# AT91SAM9CN11 register map
Vendor: Atmel; Series: SAM9CN; File version: 20130208
Registers are 32-bit, read-only, reset 0x0 unless marked. A register's access mark holds for its fields unless they carry their own. Offsets are from the block's base; [hi:lo] are bit positions; {n}, {i} and the like mark numbered series.

## AES — Advanced Encryption Standard
Base 0xF000C000; register names take the prefix AES_
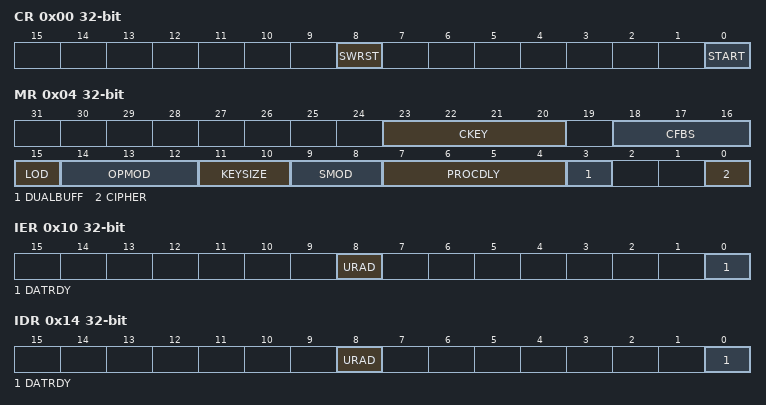
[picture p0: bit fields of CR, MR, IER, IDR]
0x00 CR wo reset not defined — Control Register
  [8] SWRST — Software Reset
  [0] START — Start Processing
0x04 MR rw — Mode Register
  [23:20] CKEY — Key
  [18:16] CFBS — Cipher Feedback Data Size
    0=SIZE_128BIT (128-bit); 1=SIZE_64BIT (64-bit); 2=SIZE_32BIT (32-bit); 3=SIZE_16BIT (16-bit); 4=SIZE_8BIT (8-bit)
  [15] LOD — Last Output Data Mode
  [14:12] OPMOD — Operation Mode
    0=ECB (ECB: Electronic Code Book mode); 1=CBC (CBC: Cipher Block Chaining mode); 2=OFB (OFB: Output Feedback mode); 3=CFB (CFB: Cipher Feedback mode); 4=CTR (CTR: Counter mode (16-bit internal counter))
  [11:10] KEYSIZE
    0=AES128 (AES Key Size is 128 bits); 1=AES192 (AES Key Size is 192 bits); 2=AES256 (AES Key Size is 256 bits)
  [9:8] SMOD — Start Mode
    0=MANUAL_START (Manual Mode); 1=AUTO_START (Auto Mode); 2=IDATAR0_START (AES_IDATAR0 access only Auto Mode)
  [7:4] PROCDLY — Processing Delay
  [3] DUALBUFF — Dual Input BUFFer
    0=INACTIVE (AES_IDATARx cannot be written during processing of previous block.); 1=ACTIVE (AES_IDATARx can be written during processing of previous block when SMOD = 0x2. It speeds up the overall runtime of large files.)
  [0] CIPHER — Processing Mode
0x10 IER wo reset not defined — Interrupt Enable Register
  [8] URAD — Unspecified Register Access Detection Interrupt Enable
  [0] DATRDY — Data Ready Interrupt Enable
0x14 IDR wo reset not defined — Interrupt Disable Register
  [8] URAD — Unspecified Register Access Detection Interrupt Disable
  [0] DATRDY — Data Ready Interrupt Disable
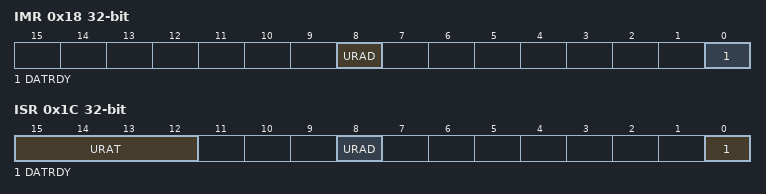
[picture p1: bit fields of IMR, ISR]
0x18 IMR — Interrupt Mask Register
  [8] URAD — Unspecified Register Access Detection Interrupt Mask
  [0] DATRDY — Data Ready Interrupt Mask
0x1C ISR — Interrupt Status Register
  [15:12] URAT — Unspecified Register Access:
    0=IDR_WR_PROCESSING (Input Data Register written during the data processing when SMOD=0x2 mode.); 1=ODR_RD_PROCESSING (Output Data Register read during the data processing.); 2=MR_WR_PROCESSING (Mode Register written during the data processing.); 3=ODR_RD_SUBKGEN (Output Data Register read during the sub-keys generation.); 4=MR_WR_SUBKGEN (Mode Register written during the sub-keys generation.); 5=WOR_RD_ACCESS (Write-only register read access.)
  [8] URAD — Unspecified Register Access Detection Status
  [0] DATRDY — Data Ready
{0x20+4i} KEYWR[{i}] (i=0..7) wo reset not defined — Key Word Register
  [31:0] KEYW — Key Word
{0x40+4i} IDATAR[{i}] (i=0..3) wo reset not defined — Input Data Register
  [31:0] IDATA — Input Data Word
{0x50+4i} ODATAR[{i}] (i=0..3) reset not defined — Output Data Register
  [31:0] ODATA — Output Data
{0x60+4i} IVR[{i}] (i=0..3) wo reset not defined — Initialization Vector Register
  [31:0] IV — Initialization Vector

## SHA — Secure Hash Algorithm
Base 0xF0014000; register names take the prefix SHA_
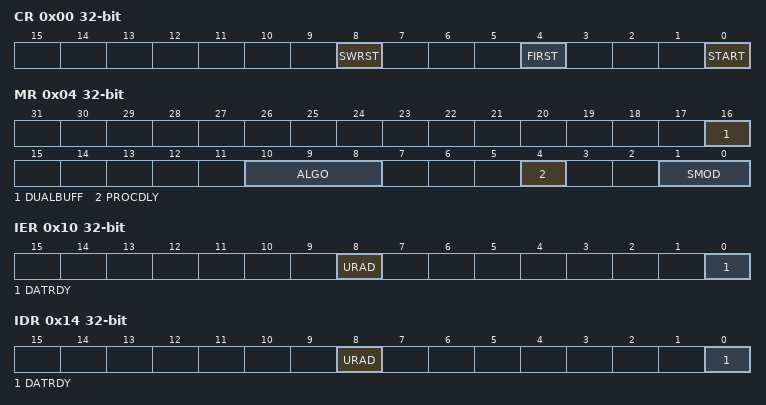
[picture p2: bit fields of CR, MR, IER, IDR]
0x00 CR wo reset not defined — Control Register
  [8] SWRST — Software Reset
  [4] FIRST — First Block of a Message
  [0] START — Start Processing
0x04 MR rw — Mode Register
  [16] DUALBUFF — Dual Input BUFFer
    0=INACTIVE (SHA_IDATARx and SHA_IODATARx cannot be written during processing of previous block.); 1=ACTIVE (SHA_IDATARx and SHA_IODATARx can be written during processing of previous block when SMOD=0x2. It speeds up the overall runtime of large files.)
  [10:8] ALGO — SHA Algorithm.
    0=SHA1 (SHA1 algorithm processed); 1=SHA256 (SHA256 algorithm processed); 4=SHA224 (SHA224 algorithm processed)
  [4] PROCDLY — Processing Delay
    0=SHORTEST (SHA processing runtime is the shortest one); 1=LONGEST (SHA processing runtime is the longest one)
  [1:0] SMOD — Start Mode
    0=MANUAL_START (Manual Mode); 1=AUTO_START (Auto Mode); 2=IDATAR0_START (SHA_IDATAR0 access only Auto Mode)
0x10 IER wo reset not defined — Interrupt Enable Register
  [8] URAD — Unspecified Register Access Detection Interrupt Enable
  [0] DATRDY — Data Ready Interrupt Enable
0x14 IDR wo reset not defined — Interrupt Disable Register
  [8] URAD — Unspecified Register Access Detection Interrupt Disable
  [0] DATRDY — Data Ready Interrupt Disable
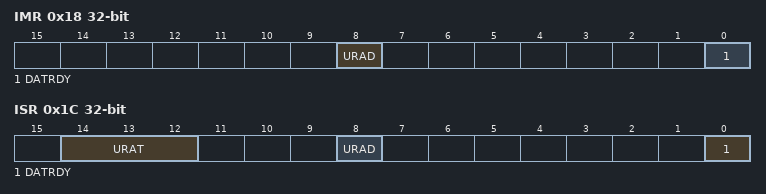
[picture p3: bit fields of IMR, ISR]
0x18 IMR — Interrupt Mask Register
  [8] URAD — Unspecified Register Access Detection Interrupt Mask
  [0] DATRDY — Data Ready Interrupt Mask
0x1C ISR — Interrupt Status Register
  [14:12] URAT — Unspecified Register Access Type
  [8] URAD — Unspecified Register Access Detection Status
  [0] DATRDY — Data Ready
{0x40+4i} IDATAR[{i}] (i=0..15) wo reset not defined — Input Data 0 Register
  [31:0] IDATA — Input Data
{0x80+4i} ODATAR[{i}] (i=0..7) reset not defined — Output Data 0 Register
  [31:0] ODATA — Output Data

## Notices in the file
SAM Software Package License
Copyright (c) 2013, Atmel Corporation
All rights reserved.
Redistribution and use in source and binary forms, with or without
modification, are permitted provided that the following condition is met:
- Redistributions of source code must retain the above copyright notice,
this list of conditions and the disclaimer below.
Atmel's name may not be used to endorse or promote products derived from
this software without specific prior written permission.
DISCLAIMER:  THIS SOFTWARE IS PROVIDED BY ATMEL "AS IS" AND ANY EXPRESS OR
IMPLIED WARRANTIES, INCLUDING, BUT NOT LIMITED TO, THE IMPLIED WARRANTIES OF
MERCHANTABILITY, FITNESS FOR A PARTICULAR PURPOSE AND NON-INFRINGEMENT ARE
DISCLAIMED. IN NO EVENT SHALL ATMEL BE LIABLE FOR ANY DIRECT, INDIRECT,
INCIDENTAL, SPECIAL, EXEMPLARY, OR CONSEQUENTIAL DAMAGES (INCLUDING, BUT NOT
LIMITED TO, PROCUREMENT OF SUBSTITUTE GOODS OR SERVICES; LOSS OF USE, DATA,
OR PROFITS; OR BUSINESS INTERRUPTION) HOWEVER CAUSED AND ON ANY THEORY OF
LIABILITY, WHETHER IN CONTRACT, STRICT LIABILITY, OR TORT (INCLUDING
NEGLIGENCE OR OTHERWISE) ARISING IN ANY WAY OUT OF THE USE OF THIS SOFTWARE,
EVEN IF ADVISED OF THE POSSIBILITY OF SUCH DAMAGE.
